# ET6801 register map
Vendor: ETMCU Inc.; File version: v0.0.1
CPU: CM7 r2p1, little endian, MPU, FPU, I-cache, D-cache, ITCM, DTCM, 4 interrupt priority bits
Registers are 32-bit, read-write, reset 0x0 unless marked. A register's access mark holds for its fields unless they carry their own. Offsets are from the block's base; [hi:lo] are bit positions; lines under a group give offsets from that group; {n}, {i} and the like mark numbered series.

## WDG0 — Provide an overview of the purpose and functionality of the peripheral: wwdg
Base 0x40402000
Same registers: WDG1 0x40403000
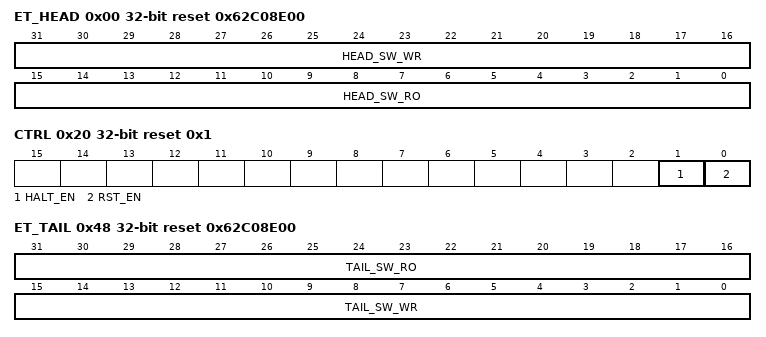
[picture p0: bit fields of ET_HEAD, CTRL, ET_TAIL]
0x00 ET_HEAD reset 0x62C08E00
  [31:16] HEAD_SW_WR — 软件测试读写寄存器，硬件无访问
  [15:0] HEAD_SW_RO ro — 软件只读上报寄存器，硬件无访问，WWDG ASCII码的CRC校验表示
0x04 LOCK
  [31:0] WWDG_LOCK — 看门狗wwdg_lock=0x1ACCE551时，允许对看门狗的寄存器进行修改，否则，不允许修改。
0x08 RELOAD reset 0xFFFFFFFF
  [31:0] WWDG_RELOAD — WWDG计数重载值，默认为最大值
0x0C CUR_VAL ro
  [31:0] WWDG_CUR_VAL — 计数器当前计数值上报
0x10 HIGH_THRESHOLD reset 0xFFFFFFFF
  [31:0] WWDG_HIGH_THRESHOLD — 窗口看门狗窗口上限值，默认为最大值
0x14 LOW_THRESHOLD
  [31:0] WWDG_LOW_THRESHOLD — 窗口看门狗窗口下限值，默认为0
0x18 EN
  [0] WWDG_EN — 看门狗模块使能，默认不使能 0-看门狗禁用；1-看门狗启用
0x1C RELOAD_REQ
  [0] WWDG_RELOAD_REQ — 喂狗请求，硬件自清零
0x20 CTRL reset 0x1
  [1] HALT_EN — 看门狗调试暂停使能，默认不使能 0-看门狗调试暂停功能禁用; 1-看门狗调试暂停功能启用
  [0] RST_EN — 看门狗复位输出使能，默认使能 0-禁用输出复位; 1-启用输出复位
0x24 MODE
  [0] WWDG_MODE — 看门狗模式配置，默认工作在窗口看门狗 0-窗口看门狗模式; 1-独立看门狗模式
0x28 WORK_MODE
  [0] WWDG_WORK_MODE — 工作模式输出配置，默认工作在模式0 0-第一轮产生中断，第二轮产生复位; 1-同一轮产生中断和复位
0x2C INT_EN
  [0] WWDG_INT_EN — 1表示使能WD MISC逻辑中断;0 取消使能
0x30 INT_MASK
  [0] WWDG_INT_MASK — 1表示屏蔽WD MISC逻辑中断;0 取消屏蔽
0x34 INT_FORCE_IND
  [0] WWDG_INT_FORCE_IND — 1表示强制产生相应的测试中断，硬件自清零
0x38 INT_CLR
  [0] WWDG_INT_CLR — 1表示清除相应的中断状态，硬件自清零
0x3C INT_RAW_RPT ro
  [0] WWDG_INT_RAW_RPT — 中断MASK前RAW 中断状态上报
0x40 INT_STATUS_RPT ro
  [0] WWDG_INT_STATUS_RPT — 中断MASK后中断状态上报
0x44 IT_RST
  [0] WWDG_IT_RST — WWDG模块集成测试复位信号
0x48 ET_TAIL reset 0x62C08E00
  [31:16] TAIL_SW_RO ro — 软件只读硬件上报寄存器
  [15:0] TAIL_SW_WR — 软件测试读写寄存器，硬件无访问，WWDG ASCII码的CRC校验表示

## EMIF0 — Provide an overview of the purpose and functionality of the peripheral: emif_0
Base 0x40605000
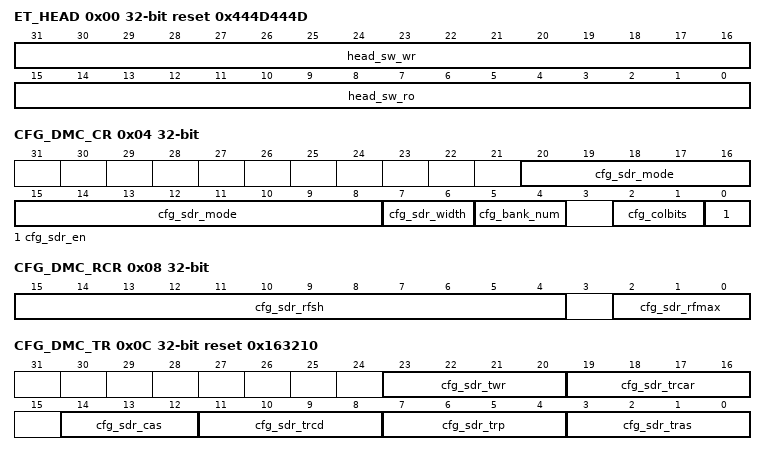
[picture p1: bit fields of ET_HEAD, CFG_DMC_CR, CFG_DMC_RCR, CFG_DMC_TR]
0x00 ET_HEAD reset 0x444D444D
  [31:16] head_sw_wr — 软件测试读写寄存器，硬件无访问
  [15:0] head_sw_ro ro — 软件只读上报寄存器，硬件无访问,DMC的ASICII 码表示
0x04 CFG_DMC_CR
  [20:8] cfg_sdr_mode — SDRAM mode Register
  [7:6] cfg_sdr_width — SDRAM Width: 00: 32bit width 01: 16bit width 1x: 8bit width
  [5:4] cfg_bank_num — Defines number of banks inside connected SDRAM devices: 00: 1 bank SDRAM devices. 01: 2 bank SDRAM devices. 10: 4 bank SDRAM devices. 11: Reserved.
  [2:1] cfg_colbits — Defines the internal page size of connected SDRAM devices: 00: 256-word pages requiring 8 column address bits. 01: 512-word pages requiring 9 column address bits. 10: 1024-word pages requiring 10 column address bits. 11: 2048-word pages requiring 11 column address bits.
  [0] cfg_sdr_en — SDRAM Controller Enable
0x08 CFG_DMC_RCR
  [15:4] cfg_sdr_rfsh — Period between auto-refresh commands issued by the controller, specified in clocks.
  [2:0] cfg_sdr_rfmax — Maximum number of rows to be refreshed at a time (tRFSH)
0x0C CFG_DMC_TR reset 0x163210
  [23:20] cfg_sdr_twr — SDRAM write recovery time (tWR), specified in clocks
  [19:16] cfg_sdr_trcar — SDRAM active to active / auto-refresh command period (tRC), specified in clocks.
  [14:12] cfg_sdr_cas — SDRAM CAS latency, specified in clocks
  [11:8] cfg_sdr_trcd — SDRAM active to read or write delay (tRCD), specified in clocks.
  [7:4] cfg_sdr_trp — SDRAM precharge command period (tRP), specified in clocks.
  [3:0] cfg_sdr_tras — SDRAM active to precharge, specified in clocks
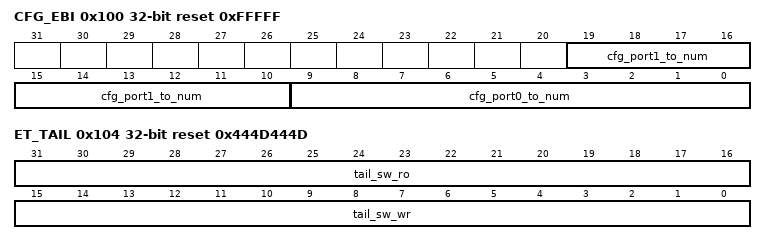
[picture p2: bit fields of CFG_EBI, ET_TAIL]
0x100 CFG_EBI reset 0xFFFFF
  [19:10] cfg_port1_to_num — SMC接口超时值
  [9:0] cfg_port0_to_num — DMC接口超时值
0x104 ET_TAIL reset 0x444D444D
  [31:16] tail_sw_ro ro — 软件只读硬件上报寄存器
  [15:0] tail_sw_wr — 软件测试读写寄存器，硬件无访问

## ADCREG — Provide an overview of the purpose and functionality of the peripheral: adcreg
Base 0x50001000
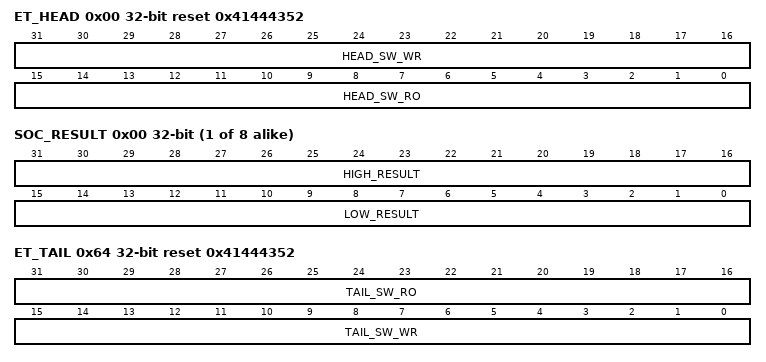
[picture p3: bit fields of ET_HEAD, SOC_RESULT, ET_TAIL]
0x00 ET_HEAD reset 0x41444352
  [31:16] HEAD_SW_WR — 软件测试读写寄存器，硬件无访问
  [15:0] HEAD_SW_RO ro — 软件只读上报寄存器，硬件无访问, ADCR的ASICII 码表示
{0x4+4i} SARC0[{i}] (i=0..7) group
  0x00 SOC_RESULT ro
    [31:16] HIGH_RESULT — SARC0虚拟通道奇数位通道结果（1/3/5...），repeat0.high_result-vc1， repeat1.high_result-vc3 ...... repeat7.high_result-vc15
    [15:0] LOW_RESULT — SARC0虚拟通道偶数位通道结果(0/2/4/...) repeat0.low_result-vc0， repeat1.high_result-vc2 ...... repeat7.high_result-vc14
{0x24+4i} SARC1[{i}] (i=0..7) group
  0x00 SOC_RESULT ro
    [31:16] HIGH_RESULT — SARC1虚拟通道奇数位通道结果（1/3/5...），repeat0.high_result-vc1， repeat1.high_result-vc3 ...... repeat7.high_result-vc15
    [15:0] LOW_RESULT — SARC1虚拟通道偶数位通道结果(0/2/4/...) repeat0.low_result-vc0， repeat1.high_result-vc2 ...... repeat7.high_result-vc14
{0x44+4i} SARC2[{i}] (i=0..7) group
  0x00 SOC_RESULT ro
    [31:16] HIGH_RESULT — SARC2虚拟通道奇数位通道结果（1/3/5...），repeat0.high_result-vc1， repeat1.high_result-vc3 ...... repeat7.high_result-vc15
    [15:0] LOW_RESULT — SARC2虚拟通道偶数位通道结果(0/2/4/...) repeat0.low_result-vc0， repeat1.high_result-vc2 ...... repeat7.high_result-vc14
0x64 ET_TAIL reset 0x41444352
  [31:16] TAIL_SW_RO ro — 软件只读上报寄存器，硬件无访问
  [15:0] TAIL_SW_WR — 软件测试读写寄存器，硬件无访问,ADCR的ASICII 码表示
